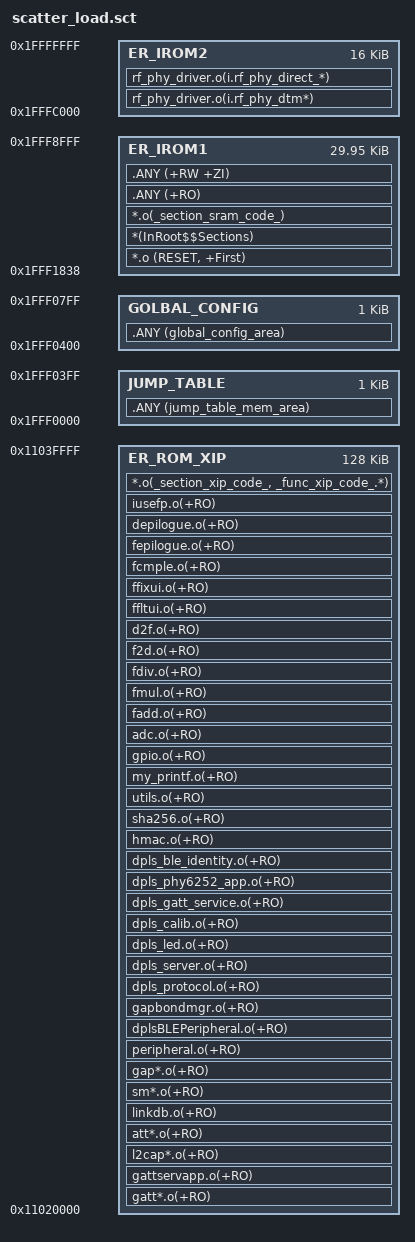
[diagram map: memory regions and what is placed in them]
; Test-DPLS PHY6252 memory map.
; Retains the proven PB-03F layout while using the SDK 3.1.2 libraries.

LR_IROM1 0x1fff1838 0x0E7C8 {
  ER_IROM1 0x1fff1838 0x077C8 {
    *.o (RESET, +First)
    *(InRoot$$Sections)
    *.o(_section_sram_code_)
    .ANY (+RO)
    .ANY (+RW +ZI)
  }
  ER_IROM2 0x1fffc000 0x04000 {
    rf_phy_driver.o(i.rf_phy_dtm*)
    rf_phy_driver.o(i.rf_phy_direct_*)
  }
}

LR_ROM_JT_GC 0x1fff0000 0x00800 {
  JUMP_TABLE 0x1fff0000 0x00400 {
    .ANY (jump_table_mem_area)
  }
  GOLBAL_CONFIG 0x1fff0400 0x00400 {
    .ANY (global_config_area)
  }
}

LR_ROM_XIP 0x11020000 0x020000 {
  ER_ROM_XIP 0x11020000 0x020000 {
    gatt*.o(+RO)
    gattservapp.o(+RO)
    l2cap*.o(+RO)
    att*.o(+RO)
    linkdb.o(+RO)
    sm*.o(+RO)
    gap*.o(+RO)
    peripheral.o(+RO)
    dplsBLEPeripheral.o(+RO)
    gapbondmgr.o(+RO)
    dpls_protocol.o(+RO)
    dpls_server.o(+RO)
    dpls_led.o(+RO)
    dpls_calib.o(+RO)
    dpls_gatt_service.o(+RO)
    dpls_phy6252_app.o(+RO)
    dpls_ble_identity.o(+RO)
    hmac.o(+RO)
    sha256.o(+RO)
    utils.o(+RO)
    my_printf.o(+RO)
    gpio.o(+RO)
    adc.o(+RO)
    fadd.o(+RO)
    fmul.o(+RO)
    fdiv.o(+RO)
    f2d.o(+RO)
    d2f.o(+RO)
    ffltui.o(+RO)
    ffixui.o(+RO)
    fcmple.o(+RO)
    fepilogue.o(+RO)
    depilogue.o(+RO)
    iusefp.o(+RO)
    *.o(_section_xip_code_, _func_xip_code_.*)
  }
}
